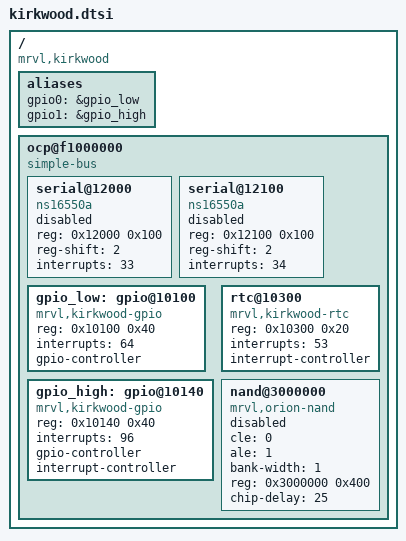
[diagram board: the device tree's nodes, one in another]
/include/ "skeleton.dtsi"

/ {
	compatible = "mrvl,kirkwood";

	aliases {
		gpio0 = &gpio_low;
		gpio1 = &gpio_high;
	};

	ocp@f1000000 {
		compatible = "simple-bus";
		ranges = <0 0xf1000000 0x4000000>;
		#address-cells = <1>;
		#size-cells = <1>;

		serial@12000 {
			compatible = "ns16550a";
			reg = <0x12000 0x100>;
			reg-shift = <2>;
			interrupts = <33>;
			/* set clock-frequency in board dts */
			status = "disabled";
		};

		serial@12100 {
			compatible = "ns16550a";
			reg = <0x12100 0x100>;
			reg-shift = <2>;
			interrupts = <34>;
			/* set clock-frequency in board dts */
			status = "disabled";
		};

		gpio_low: gpio@10100 {
			compatible = "mrvl,kirkwood-gpio","mrvl,orion-gpio";
			reg = <0x10100 0x40>;
			interrupts = <64>;
			#gpio-cells = <2>;
			gpio-controller;
		};

		gpio_high: gpio@10140 {
			compatible = "mrvl,kirkwood-gpio","mrvl,orion-gpio";
			reg = <0x10140 0x40>;
			interrupts = <96>;
			#gpio-cells = <2>;
			gpio-controller;
			interrupt-controller;
		};

		rtc@10300 {
			compatible = "mrvl,kirkwood-rtc", "mrvl,orion-rtc";
			reg = <0x10300 0x20>;
			interrupts = <53>;
			interrupt-controller;
		};

		nand@3000000 {
			#address-cells = <1>;
			#size-cells = <1>;
			cle = <0>;
			ale = <1>;
			bank-width = <1>;
			compatible = "mrvl,orion-nand";
			reg = <0x3000000 0x400>;
			chip-delay = <25>;
			/* set partition map and/or chip-delay in board dts */
			status = "disabled";
		};
	};
};
